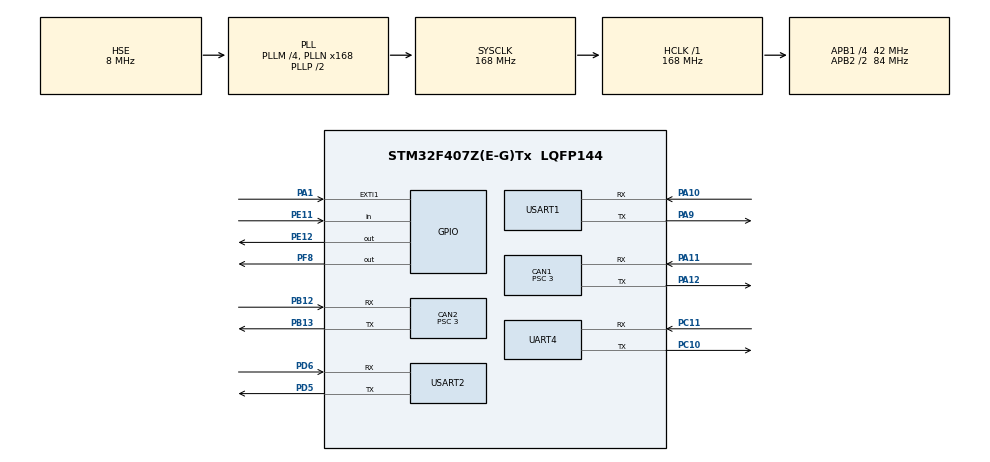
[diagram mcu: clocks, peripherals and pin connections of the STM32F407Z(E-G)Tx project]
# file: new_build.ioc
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CAN1.BS1=CAN_BS1_9TQ
CAN1.BS2=CAN_BS2_4TQ
CAN1.CalculateBaudRate=1000000
CAN1.CalculateTimeBit=1000
CAN1.CalculateTimeQuantum=71.42857142857143
CAN1.Prescaler=3
CAN1.RFLM=DISABLE
CAN2.BS1=CAN_BS1_9TQ
CAN2.BS2=CAN_BS2_4TQ
CAN2.CalculateBaudRate=1000000
CAN2.CalculateTimeBit=1000
CAN2.CalculateTimeQuantum=71.42857142857143
CAN2.Prescaler=3
CAN2.RFLM=DISABLE
Dma.Request0=USART1_TX
Dma.Request1=USART1_RX
Dma.Request2=UART4_RX
Dma.Request3=USART2_RX
Dma.Request4=USART2_TX
Dma.UART4_RX.2.Direction=DMA_PERIPH_TO_MEMORY
Dma.UART4_RX.2.FIFOMode=DMA_FIFOMODE_DISABLE
Dma.UART4_RX.2.Instance=DMA1_Stream2
Dma.UART4_RX.2.MemDataAlignment=DMA_MDATAALIGN_BYTE
Dma.UART4_RX.2.MemInc=DMA_MINC_ENABLE
Dma.UART4_RX.2.Mode=DMA_NORMAL
Dma.UART4_RX.2.PeriphDataAlignment=DMA_PDATAALIGN_BYTE
Dma.UART4_RX.2.PeriphInc=DMA_PINC_DISABLE
Dma.UART4_RX.2.Priority=DMA_PRIORITY_LOW
Dma.USART1_RX.1.Direction=DMA_PERIPH_TO_MEMORY
Dma.USART1_RX.1.FIFOMode=DMA_FIFOMODE_DISABLE
Dma.USART1_RX.1.Instance=DMA2_Stream2
Dma.USART1_RX.1.MemDataAlignment=DMA_MDATAALIGN_BYTE
Dma.USART1_RX.1.MemInc=DMA_MINC_ENABLE
Dma.USART1_RX.1.Mode=DMA_NORMAL
Dma.USART1_RX.1.PeriphDataAlignment=DMA_PDATAALIGN_BYTE
Dma.USART1_RX.1.PeriphInc=DMA_PINC_DISABLE
Dma.USART1_RX.1.Priority=DMA_PRIORITY_MEDIUM
Dma.USART1_TX.0.Direction=DMA_MEMORY_TO_PERIPH
Dma.USART1_TX.0.FIFOMode=DMA_FIFOMODE_DISABLE
Dma.USART1_TX.0.Instance=DMA2_Stream7
Dma.USART1_TX.0.MemDataAlignment=DMA_MDATAALIGN_BYTE
Dma.USART1_TX.0.MemInc=DMA_MINC_ENABLE
Dma.USART1_TX.0.Mode=DMA_NORMAL
Dma.USART1_TX.0.PeriphDataAlignment=DMA_PDATAALIGN_BYTE
Dma.USART1_TX.0.PeriphInc=DMA_PINC_DISABLE
Dma.USART1_TX.0.Priority=DMA_PRIORITY_MEDIUM
Dma.USART2_RX.3.Direction=DMA_PERIPH_TO_MEMORY
Dma.USART2_RX.3.FIFOMode=DMA_FIFOMODE_DISABLE
Dma.USART2_RX.3.Instance=DMA1_Stream5
Dma.USART2_RX.3.MemDataAlignment=DMA_MDATAALIGN_BYTE
Dma.USART2_RX.3.MemInc=DMA_MINC_ENABLE
Dma.USART2_RX.3.Mode=DMA_CIRCULAR
Dma.USART2_RX.3.PeriphDataAlignment=DMA_PDATAALIGN_BYTE
Dma.USART2_RX.3.PeriphInc=DMA_PINC_DISABLE
Dma.USART2_RX.3.Priority=DMA_PRIORITY_LOW
Dma.USART2_TX.4.Direction=DMA_MEMORY_TO_PERIPH
Dma.USART2_TX.4.FIFOMode=DMA_FIFOMODE_DISABLE
Dma.USART2_TX.4.Instance=DMA1_Stream6
Dma.USART2_TX.4.MemDataAlignment=DMA_MDATAALIGN_BYTE
Dma.USART2_TX.4.MemInc=DMA_MINC_ENABLE
Dma.USART2_TX.4.Mode=DMA_CIRCULAR
Dma.USART2_TX.4.PeriphDataAlignment=DMA_PDATAALIGN_BYTE
Dma.USART2_TX.4.PeriphInc=DMA_PINC_DISABLE
Dma.USART2_TX.4.Priority=DMA_PRIORITY_LOW
FREERTOS.INCLUDE_xTaskAbortDelay=1
FREERTOS.Tasks01=defaultTask,24,128,StartDefaultTask,Default,NULL,Dynamic,NULL,NULL;LogTaskHandle,24,128,LogTestTask,As external,NULL,Dynamic,NULL,NULL;DebugTaskHandle,24,128,DebugTask,As external,NULL,Dynamic,NULL,NULL;MotorTaskHandle,24,128,MotorTask,As external,NULL,Dynamic,NULL,NULL
FREERTOS.configENABLE_FPU=1
FREERTOS.configGENERATE_RUN_TIME_STATS=0
FREERTOS.configTOTAL_HEAP_SIZE=65536
FREERTOS.configUSE_IDLE_HOOK=1
Mcu.Family=STM32F4
Mcu.Name=STM32F407Z(E-G)Tx
Mcu.Package=LQFP144
NVIC.CAN1_RX0_IRQn=true\:5\:0\:false\:false\:true\:true\:true\:true\:true
NVIC.CAN1_RX1_IRQn=true\:5\:0\:false\:false\:true\:true\:true\:true\:true
NVIC.CAN2_RX0_IRQn=true\:5\:0\:false\:false\:true\:true\:true\:true\:true
NVIC.CAN2_RX1_IRQn=true\:5\:0\:false\:false\:true\:true\:true\:true\:true
NVIC.DMA1_Stream2_IRQn=true\:5\:0\:false\:false\:true\:true\:false\:true\:true
NVIC.DMA1_Stream5_IRQn=true\:5\:0\:false\:false\:true\:true\:false\:true\:true
NVIC.DMA1_Stream6_IRQn=true\:5\:0\:false\:false\:true\:true\:false\:true\:true
NVIC.DMA2_Stream2_IRQn=true\:5\:0\:false\:false\:true\:true\:false\:true\:true
NVIC.DMA2_Stream7_IRQn=true\:5\:0\:false\:false\:true\:true\:false\:true\:true
NVIC.EXTI1_IRQn=true\:5\:0\:false\:false\:true\:true\:true\:true\:true
NVIC.PriorityGroup=NVIC_PRIORITYGROUP_4
NVIC.TIM2_IRQn=true\:15\:0\:false\:false\:true\:false\:false\:true\:true
NVIC.TimeBase=TIM2_IRQn
NVIC.TimeBaseIP=TIM2
NVIC.UART4_IRQn=true\:5\:0\:false\:false\:true\:true\:true\:true\:true
NVIC.USART1_IRQn=true\:5\:0\:false\:false\:true\:true\:true\:true\:true
NVIC.USART2_IRQn=true\:5\:0\:false\:false\:true\:true\:true\:true\:true
PA1.Signal=GPXTI1
PA10.Mode=Asynchronous
PA10.Signal=USART1_RX
PA11.Mode=CAN_Activate
PA11.Signal=CAN1_RX
PA12.Mode=CAN_Activate
PA12.Signal=CAN1_TX
PA13.Mode=Serial_Wire
PA13.Signal=SYS_JTMS-SWDIO
PA14.Mode=Serial_Wire
PA14.Signal=SYS_JTCK-SWCLK
PA9.Mode=Asynchronous
PA9.Signal=USART1_TX
PB12.Mode=CAN_Activate
PB12.Signal=CAN2_RX
PB13.Mode=CAN_Activate
PB13.Signal=CAN2_TX
PC10.Mode=Asynchronous
PC10.Signal=UART4_TX
PC11.Mode=Asynchronous
PC11.Signal=UART4_RX
PD5.Mode=Asynchronous
PD5.Signal=USART2_TX
PD6.Mode=Asynchronous
PD6.Signal=USART2_RX
PE11.GPIO_Mode=GPIO_MODE_INPUT
PE11.GPIO_PuPd=GPIO_PULLUP
PE11.Signal=GPIO_Input
PE12.GPIO_PuPd=GPIO_PULLUP
PE12.GPIO_Speed=GPIO_SPEED_FREQ_VERY_HIGH
PE12.PinState=GPIO_PIN_SET
PE12.Signal=GPIO_Output
PF8.GPIO_PuPd=GPIO_NOPULL
PF8.GPIO_Speed=GPIO_SPEED_FREQ_VERY_HIGH
PF8.PinState=GPIO_PIN_SET
PF8.Signal=GPIO_Output
PH0-OSC_IN.Mode=HSE-External-Oscillator
PH0-OSC_IN.Signal=RCC_OSC_IN
PH1-OSC_OUT.Mode=HSE-External-Oscillator
PH1-OSC_OUT.Signal=RCC_OSC_OUT
ProjectManager.HeapSize=0x200
ProjectManager.StackSize=0x400
ProjectManager.TargetToolchain=Makefile
RCC.48MHZClocksFreq_Value=84000000
RCC.AHBFreq_Value=168000000
RCC.APB1CLKDivider=RCC_HCLK_DIV4
RCC.APB1Freq_Value=42000000
RCC.APB1TimFreq_Value=84000000
RCC.APB2CLKDivider=RCC_HCLK_DIV2
RCC.APB2Freq_Value=84000000
RCC.APB2TimFreq_Value=168000000
RCC.CortexFreq_Value=168000000
RCC.HCLKFreq_Value=168000000
RCC.HSE_VALUE=8000000
RCC.HSI_VALUE=16000000
RCC.LSE_VALUE=32768
RCC.PLLM=4
RCC.PLLN=168
RCC.PLLSourceVirtual=RCC_PLLSOURCE_HSE
RCC.SYSCLKFreq_VALUE=168000000
RCC.SYSCLKSource=RCC_SYSCLKSOURCE_PLLCLK
RCC.VCOOutputFreq_Value=336000000
STMicroelectronics.X-CUBE-ALGOBUILD.1.3.0.LibraryCcDSPOoLibraryJjDSPOoLibrary=true
UART4.VirtualMode=Asynchronous
USART1.VirtualMode=VM_ASYNC
USART2.VirtualMode=VM_ASYNC
VP_FREERTOS_VS_CMSIS_V2.Mode=CMSIS_V2
VP_STMicroelectronics.X-CUBE-ALGOBUILD_VS_DSPOoLibraryJjLibrary_1.3.0_1.3.0.Mode=DSPOoLibraryJjLibrary
VP_SYS_VS_tim2.Mode=TIM2
board=custom

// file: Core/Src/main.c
/* USER CODE BEGIN Header */
/**
  ******************************************************************************
  * @file           : main.c
  * @brief          : Main program body
  ******************************************************************************
  * @attention
  *
  * Copyright (c) 2024 STMicroelectronics.
  * All rights reserved.
  *
  * This software is licensed under terms that can be found in the LICENSE file
  * in the root directory of this software component.
  * If no LICENSE file comes with this software, it is provided AS-IS.
  *
  ******************************************************************************
  */
/* USER CODE END Header */
#include "main.h"
#include "cmsis_os.h"
#include "can.h"
#include "dma.h"
#include "usart.h"
#include "gpio.h"

/* USER CODE BEGIN Includes */

/* App层头文件接口 */
#include "robot.h"
#include "robot_def.h"
/* Bsp层头文件接口 */
#include "bsp_log.h"

/* USER CODE END Includes */

void SystemClock_Config(void);
void MX_FREERTOS_Init(void);

int main(void)
{

  /* MCU Configuration--------------------------------------------------------*/

  /* Reset of all peripherals, Initializes the Flash interface and the Systick. */
  HAL_Init();

  /* Configure the system clock */
  SystemClock_Config();

  /* Initialize all configured peripherals */
  MX_GPIO_Init();
  MX_DMA_Init();
  MX_CAN1_Init();
  MX_CAN2_Init();
  MX_USART1_UART_Init();
  MX_UART4_Init();
  MX_USART2_UART_Init();
  /* USER CODE BEGIN 2 */
  Robot_Init();
  LOG_CLEAR();
  LOGINFO("FreeRTOS is Ready!\n");

  /* USER CODE END 2 */

  /* Init scheduler */
  osKernelInitialize();

  /* Call init function for freertos objects (in cmsis_os2.c) */
  MX_FREERTOS_Init();

  /* Start scheduler */
  osKernelStart();

  /* We should never get here as control is now taken by the scheduler */

  /* Infinite loop */
  while (1)
  {

  }
}

void SystemClock_Config(void)
{
  RCC_OscInitTypeDef RCC_OscInitStruct = {0};
  RCC_ClkInitTypeDef RCC_ClkInitStruct = {0};

  /** Configure the main internal regulator output voltage
  */
  __HAL_RCC_PWR_CLK_ENABLE();
  __HAL_PWR_VOLTAGESCALING_CONFIG(PWR_REGULATOR_VOLTAGE_SCALE1);

  /** Initializes the RCC Oscillators according to the specified parameters
  * in the RCC_OscInitTypeDef structure.
  */
  RCC_OscInitStruct.OscillatorType = RCC_OSCILLATORTYPE_HSE;
  RCC_OscInitStruct.HSEState = RCC_HSE_ON;
  RCC_OscInitStruct.PLL.PLLState = RCC_PLL_ON;
  RCC_OscInitStruct.PLL.PLLSource = RCC_PLLSOURCE_HSE;
  RCC_OscInitStruct.PLL.PLLM = 4;
  RCC_OscInitStruct.PLL.PLLN = 168;
  RCC_OscInitStruct.PLL.PLLP = RCC_PLLP_DIV2;
  RCC_OscInitStruct.PLL.PLLQ = 4;
  if (HAL_RCC_OscConfig(&RCC_OscInitStruct) != HAL_OK)
  {
    Error_Handler();
  }

  /** Initializes the CPU, AHB and APB buses clocks
  */
  RCC_ClkInitStruct.ClockType = RCC_CLOCKTYPE_HCLK|RCC_CLOCKTYPE_SYSCLK
                              |RCC_CLOCKTYPE_PCLK1|RCC_CLOCKTYPE_PCLK2;
  RCC_ClkInitStruct.SYSCLKSource = RCC_SYSCLKSOURCE_PLLCLK;
  RCC_ClkInitStruct.AHBCLKDivider = RCC_SYSCLK_DIV1;
  RCC_ClkInitStruct.APB1CLKDivider = RCC_HCLK_DIV4;
  RCC_ClkInitStruct.APB2CLKDivider = RCC_HCLK_DIV2;

  if (HAL_RCC_ClockConfig(&RCC_ClkInitStruct, FLASH_LATENCY_5) != HAL_OK)
  {
    Error_Handler();
  }
}

void HAL_TIM_PeriodElapsedCallback(TIM_HandleTypeDef *htim)
{
  if (htim->Instance == TIM2) {
    HAL_IncTick();
  }
}

void Error_Handler(void)
{
  __disable_irq();
  while (1)
  {
  }
}

#ifdef  USE_FULL_ASSERT
/**
  * @brief  Reports the name of the source file and the source line number
  *         where the assert_param error has occurred.
  * @param  file: pointer to the source file name
  * @param  line: assert_param error line source number
  * @retval None
  */
void assert_failed(uint8_t *file, uint32_t line)
{
  /* USER CODE BEGIN 6 */
  /* User can add his own implementation to report the file name and line number,
     ex: printf("Wrong parameters value: file %s on line %d\r\n", file, line) */
     for(;;)
     {
      LOGERROR("Wrong parameters value: file %s on line %d\r\n", file, line);
     }
  /* USER CODE END 6 */
}
#endif /* USE_FULL_ASSERT */

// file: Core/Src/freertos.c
/* USER CODE BEGIN Header */
/**
  ******************************************************************************
  * File Name          : freertos.c
  * Description        : Code for freertos applications
  ******************************************************************************
  * @attention
  *
  * Copyright (c) 2024 STMicroelectronics.
  * All rights reserved.
  *
  * This software is licensed under terms that can be found in the LICENSE file
  * in the root directory of this software component.
  * If no LICENSE file comes with this software, it is provided AS-IS.
  *
  ******************************************************************************
  */
/* USER CODE END Header */

#include "FreeRTOS.h"
#include "task.h"
#include "main.h"
#include "cmsis_os.h"
#include "bsp_log.h"

/* Definitions for defaultTask */
osThreadId_t defaultTaskHandle;
const osThreadAttr_t defaultTask_attributes = {
  .name = "defaultTask",
  .stack_size = 128 * 4,
  .priority = (osPriority_t) osPriorityNormal,
};

void StartDefaultTask(void *argument);

void MX_FREERTOS_Init(void); /* (MISRA C 2004 rule 8.1) */

void MX_FREERTOS_Init(void) {

  /* Create the thread(s) */
  /* creation of defaultTask */
  defaultTaskHandle = osThreadNew(StartDefaultTask, NULL, &defaultTask_attributes);

}

void StartDefaultTask(void *argument)
{
  /* USER CODE BEGIN StartDefaultTask */
  /* Infinite loop */
  for(;;)
  {
    // 一般可以在这个任务线程完成一些比较额外的初始化工作(但还是建议分app,实现不同的app数据池被限制在自己的线程中)
    // LOGINFO("task is running!");
    osThreadTerminate(defaultTaskHandle); // 避免空置和切换占用cpu
    // osDelay(1);
  }
  /* USER CODE END StartDefaultTask */
}
